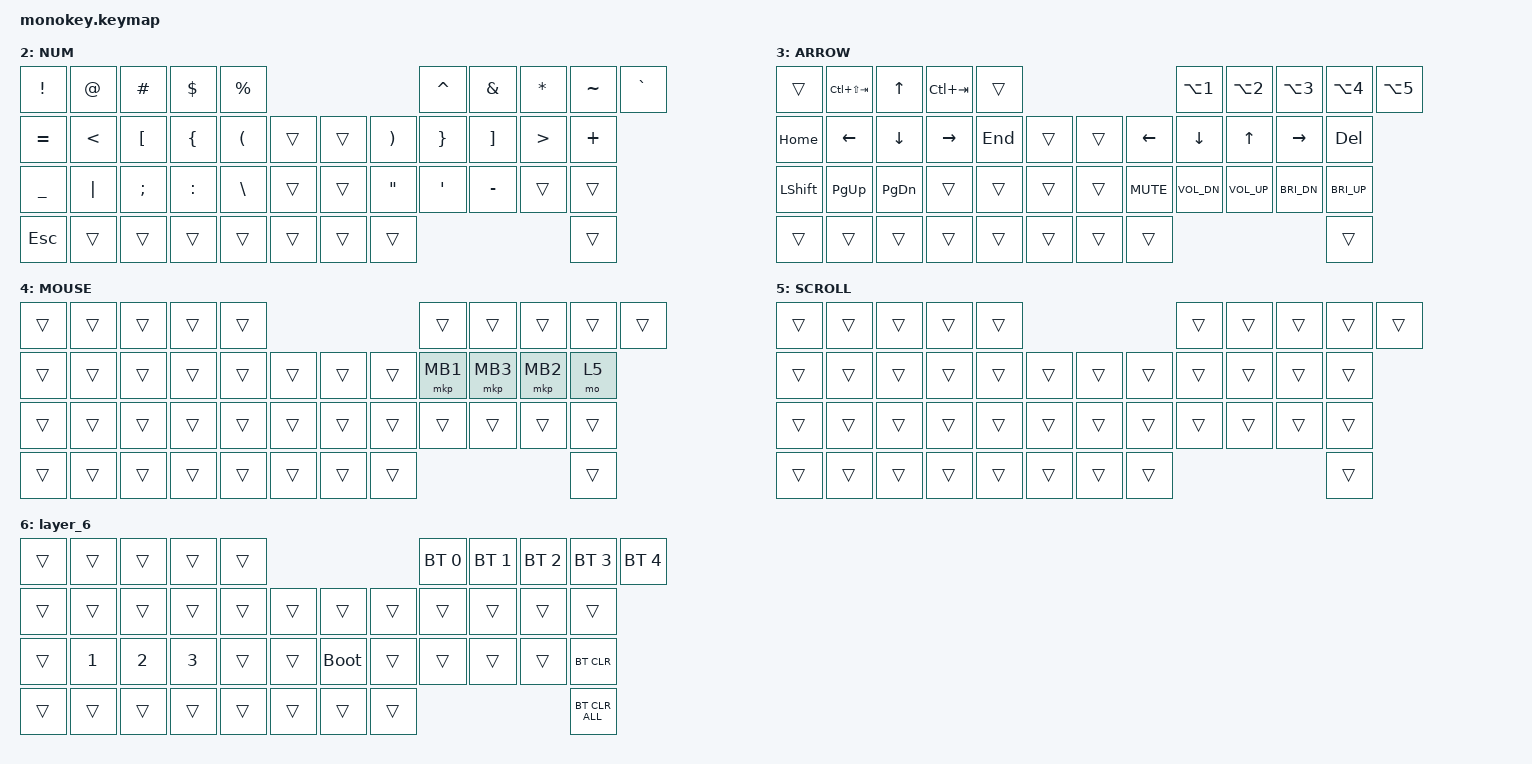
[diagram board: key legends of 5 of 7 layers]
#include <behaviors.dtsi>
#include <dt-bindings/zmk/bt.h>
#include <dt-bindings/zmk/keys.h>
#include <dt-bindings/zmk/mouse.h>

#define MOUSE 4
#define SCROLL 5
#define NUM 6

&mt {
    flavor = "balanced";
    quick-tap-ms = <175>;
};

/ {
    macros {
        to_layer_0: to_layer_0 {
            compatible = "zmk,behavior-macro-one-param";
            #binding-cells = <1>;
            bindings = <&to 0 &macro_param_1to1 &kp MACRO_PLACEHOLDER>;
            label = "TO_LAYER_0";
        };
    };

    behaviors {
        lt_to_layer_0: lt_to_layer_0 {
            compatible = "zmk,behavior-hold-tap";
            label = "LT_TO_LAYER_0";
            bindings = <&mo>, <&to_layer_0>;
            #binding-cells = <2>;
            tapping-term-ms = <200>;
        };
    };

    combos {
        compatible = "zmk,combos";

        tab {
            bindings = <&kp TAB>;
            key-positions = <11 12>;
        };

        shift_tab {
            bindings = <&kp LS(TAB)>;
            key-positions = <12 13>;
        };

    };

    keymap {
        compatible = "zmk,keymap";

        default_layer {
          bindings = <
&kp Q      &kp W           &kp E         &kp R             &kp T                                &kp Y          &kp U                &kp I     &kp O     &kp P
&kp A      &kp S           &kp D         &kp F             &kp G                                &kp H          &kp J                &kp K     &kp L     &kp MINUS
&mt LSHIFT Z  &kp X        &kp C         &kp V             &kp B                                &kp N          &kp M                &kp COMMA     &kp DOT       &mt RSHIFT SLASH
&lt 6 TAB     &kp LCTRL    &kp LEFT_ALT  &mt LCMD INT_MUHENKAN  &lt 1 SPACE  &lt_to_layer_0 2 BACKSPACE    &lt 3 ENTER  &mt RCMD INT_HENKAN    &kp RCTRL     &sk LSHIFT
            >;

            sensor-bindings = <&inc_dec_kp PG_UP PAGE_DOWN>;
        };

        FUNCTION {
            bindings = <
&kp F1  &kp F2   &kp F3   &kp F4   &trans                    &kp NUMBER_1  &kp NUMBER_2  &kp NUMBER_3  &trans  &trans
&kp F5  &kp F6   &kp F7   &kp F8   &trans  &trans    &trans  &kp NUMBER_4  &kp NUMBER_5  &kp NUMBER_6  &kp PLUS      &kp MINUS
&kp F9  &kp F10  &kp F11  &kp F12  &trans  &trans    &trans  &kp NUMBER_7  &kp NUMBER_8  &kp NUMBER_9  &kp ASTERISK  &kp SLASH
&trans  &trans   &trans   &trans   &trans  &trans    &kp PERIOD  &kp NUMBER_0  &trans                                              &trans
            >;
        };

        NUM {
            bindings = <
&kp EXCLAMATION  &kp AT_SIGN  &kp HASH  &kp DOLLAR  &kp PERCENT                                                 &kp CARET  &kp AMPERSAND  &kp ASTERISK  &kp TILDE  &kp GRAVE
&kp EQUAL  &kp LESS_THAN  &kp LEFT_BRACKET  &kp LEFT_BRACE  &kp LEFT_PARENTHESIS  &trans    &trans  &kp RIGHT_PARENTHESIS  &kp RIGHT_BRACE  &kp RIGHT_BRACKET  &kp GREATER_THAN  &kp PLUS
&kp UNDERSCORE  &kp PIPE  &kp SEMICOLON  &kp COLON  &kp BACKSLASH  &trans    &trans  &kp DOUBLE_QUOTES  &kp SINGLE_QUOTE  &kp MINUS  &trans  &trans
&kp ESC  &trans  &trans  &trans  &trans  &trans    &trans  &trans                                &trans
            >;
        };

        ARROW {
            bindings = <
&trans          &kp LC(LS(TAB))  &kp UP_ARROW    &kp LC(TAB)      &trans                                          &kp LA(NUMBER_1)  &kp LA(NUMBER_2)  &kp LA(NUMBER_3)  &kp LA(NUMBER_4)  &kp LA(NUMBER_5)
&kp HOME        &kp LEFT_ARROW   &kp DOWN_ARROW  &kp RIGHT_ARROW  &kp END  &trans    &trans          &kp LEFT_ARROW    &kp DOWN_ARROW    &kp UP_ARROW      &kp RIGHT_ARROW   &kp DELETE
&kp LEFT_SHIFT  &kp PG_UP        &kp PG_DN       &trans           &trans   &trans    &trans          &kp C_MUTE        &kp C_VOL_DN      &kp C_VOL_UP      &kp C_BRI_DN      &kp C_BRI_UP
&trans          &trans           &trans          &trans           &trans   &trans    &trans          &trans                                                                  &trans
            >;

            sensor-bindings = <&inc_dec_kp LC(PAGE_UP) LC(PAGE_DOWN)>;
        };

        MOUSE {
            bindings = <
&trans  &trans  &trans  &trans  &trans                    &trans  &trans    &trans    &trans    &trans
&trans  &trans  &trans  &trans  &trans  &trans    &trans  &trans  &mkp MB1  &mkp MB3  &mkp MB2  &mo 5
&trans  &trans  &trans  &trans  &trans  &trans    &trans  &trans  &trans    &trans    &trans    &trans
&trans  &trans  &trans  &trans  &trans  &trans    &trans  &trans                                &trans
            >;
        };

        SCROLL {
            bindings = <
&trans  &trans  &trans  &trans  &trans                    &trans  &trans  &trans  &trans  &trans
&trans  &trans  &trans  &trans  &trans  &trans    &trans  &trans  &trans  &trans  &trans  &trans
&trans  &trans  &trans  &trans  &trans  &trans    &trans  &trans  &trans  &trans  &trans  &trans
&trans  &trans  &trans  &trans  &trans  &trans    &trans  &trans                          &trans
            >;
        };

        layer_6 {
            bindings = <
&trans  &trans        &trans        &trans        &trans                         &bt BT_SEL 0  &bt BT_SEL 1  &bt BT_SEL 2  &bt BT_SEL 3  &bt BT_SEL 4
&trans  &trans        &trans        &trans        &trans  &trans    &trans       &trans        &trans        &trans        &trans        &trans
&trans  &kp NUMBER_1  &kp NUMBER_2  &kp NUMBER_3  &trans  &trans    &bootloader  &trans        &trans        &trans        &trans        &bt BT_CLR
&trans  &trans        &trans        &trans        &trans  &trans    &trans       &trans                                                  &bt BT_CLR_ALL
            >;
        };
    };
};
